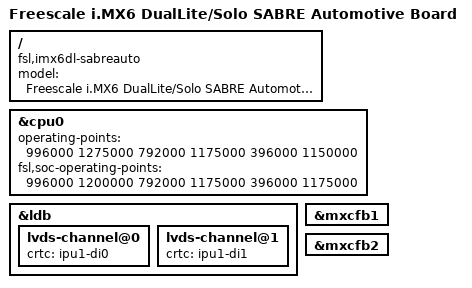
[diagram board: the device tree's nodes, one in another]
// SPDX-License-Identifier: GPL-2.0
//
// Copyright (C) 2013 Freescale Semiconductor, Inc.

/dts-v1/;

#include "imx6dl.dtsi"
#include "imx6qdl-sabreauto.dtsi"

/ {
	model = "Freescale i.MX6 DualLite/Solo SABRE Automotive Board";
	compatible = "fsl,imx6dl-sabreauto", "fsl,imx6dl";
};

&cpu0 {
	operating-points = <
		/* kHz    uV */
		996000  1275000
		792000  1175000
		396000  1150000
	>;
	fsl,soc-operating-points = <
		/* ARM kHz  SOC-PU uV */
		996000	1200000
		792000	1175000
		396000	1175000
	>;
};

&ldb {
	lvds-channel@0 {
		crtc = "ipu1-di0";
	};

	lvds-channel@1 {
		crtc = "ipu1-di1";
	};
};

&mxcfb1 {
	status = "okay";
};

&mxcfb2 {
	status = "okay";
};
